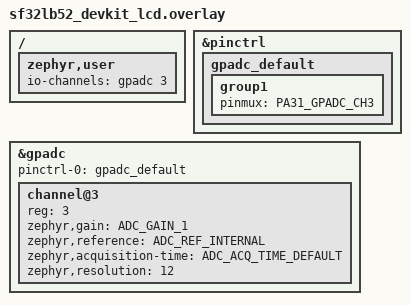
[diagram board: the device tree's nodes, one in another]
/*
 * SPDX-FileCopyrightText: Copyright The Zephyr Project Contributors
 * SPDX-License-Identifier: Apache-2.0
 */

#include <zephyr/dt-bindings/adc/adc.h>

/ {
	zephyr,user {
		io-channels = <&gpadc 3>;
	};
};

&pinctrl {
	gpadc_default: gpadc_default {
		group1 {
			pinmux = <PA31_GPADC_CH3>;
		};
	};
};

&gpadc {
	status = "okay";
	pinctrl-0 = <&gpadc_default>;
	pinctrl-names = "default";
	#address-cells = <1>;
	#size-cells = <0>;

	channel@3 {
		reg = <3>;
		zephyr,gain = "ADC_GAIN_1";
		zephyr,reference = "ADC_REF_INTERNAL";
		zephyr,acquisition-time = <ADC_ACQ_TIME_DEFAULT>;
		zephyr,resolution = <12>;
	};
};
